# R7FA4W1AD register map
Vendor: Renesas; Series: RA4; File version: 1.0
CPU: CM4 r0p1, little endian, MPU, FPU, VTOR, 4 interrupt priority bits
Registers are 8-bit, read-write, reset 0x0 unless marked. A register's access mark holds for its fields unless they carry their own. Offsets are from the block's base; [hi:lo] are bit positions.

## DMAC0 — Direct memory access controller 0
Base 0x40005000
Same registers: DMAC1 0x40005040, DMAC2 0x40005080, DMAC3 0x400050C0
0x00 DMSAR 32-bit — DMA Source Address Register
  [31:0] DMSAR — Specifies the transfer source start address.
0x04 DMDAR 32-bit — DMA Destination Address Register
  [31:0] DMDAR — Specifies the transfer destination start address.
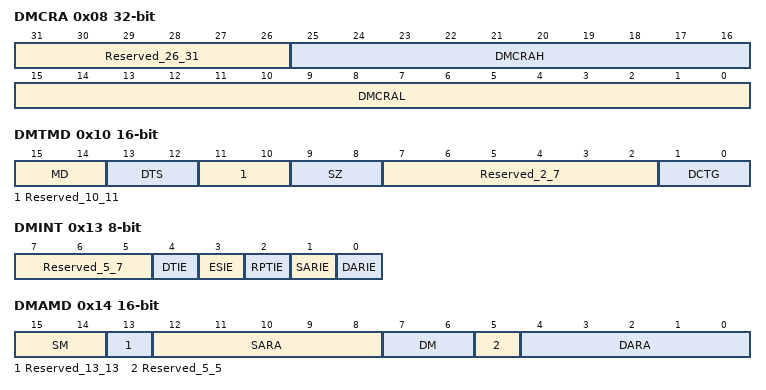
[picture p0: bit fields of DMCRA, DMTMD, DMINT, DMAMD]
0x08 DMCRA 32-bit — DMA Transfer Count Register
  [31:26] Reserved_26_31 — These bits are read as 000000. The write value should be 000000.
  [25:16] DMCRAH — Upper bits of transfer count
  [15:0] DMCRAL — Lower bits of transfer count
0x0C DMCRB 16-bit — DMA Block Transfer Count Register
  [15:0] DMCRB — Specifies the number of block transfer operations or repeat transfer operations.
0x10 DMTMD 16-bit — DMA Transfer Mode Register
  [15:14] MD — Transfer Mode Select
  [13:12] DTS — Repeat Area Select
  [11:10] Reserved_10_11 — These bits are read as 00. The write value should be 00.
  [9:8] SZ — Transfer Data Size Select
  [7:2] Reserved_2_7 — These bits are read as 000000. The write value should be 000000.
  [1:0] DCTG — Transfer Request Source Select
0x13 DMINT — DMA Interrupt Setting Register
  [7:5] Reserved_5_7 — These bits are read as 000. The write value should be 000.
  [4] DTIE — Transfer End Interrupt Enable
  [3] ESIE — Transfer Escape End Interrupt Enable
  [2] RPTIE — Repeat Size End Interrupt Enable
  [1] SARIE — Source Address Extended Repeat Area Overflow Interrupt Enable
  [0] DARIE — Destination Address Extended Repeat Area Overflow Interrupt Enable
0x14 DMAMD 16-bit — DMA Address Mode Register
  [15:14] SM — Source Address Update Mode
  [13] Reserved_13_13 — This bit is read as 0. The write value should be 0.
  [12:8] SARA — Source Address Extended Repeat Area Specifies the extended repeat area on the source address. For details on the settings.
  [7:6] DM — Destination Address Update Mode
  [5] Reserved_5_5 — This bit is read as 0. The write value should be 0.
  [4:0] DARA — Destination Address Extended Repeat Area Specifies the extended repeat area on the destination address. For details on the settings.
0x18 DMOFR 32-bit — DMA Offset Register
  [31:0] DMOFR — Specifies the offset when offset addition is selected as the address update mode for transfer source or destination.
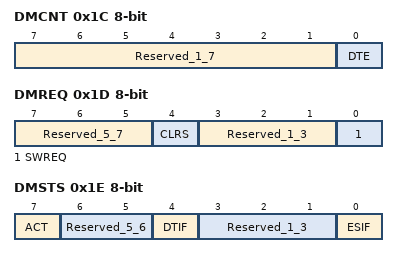
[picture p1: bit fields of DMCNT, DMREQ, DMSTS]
0x1C DMCNT — DMA Transfer Enable Register
  [7:1] Reserved_1_7 — These bits are read as 0000000. The write value should be 0000000.
  [0] DTE read-modifies — DMA Transfer Enable
0x1D DMREQ — DMA Software Start Register
  [7:5] Reserved_5_7 — These bits are read as 000. The write value should be 000.
  [4] CLRS — DMA Software Start Bit Auto Clear Select
  [3:1] Reserved_1_3 — These bits are read as 000. The write value should be 000.
  [0] SWREQ read-modifies — DMA Software Start
0x1E DMSTS — DMA Status Register
  [7] ACT ro — DMA Active Flag
  [6:5] Reserved_5_6 — These bits are read as 00. The write value should be 00.
  [4] DTIF write-0-clears read-modifies — Transfer End Interrupt Flag
  [3:1] Reserved_1_3 — These bits are read as 000. The write value should be 000.
  [0] ESIF write-0-clears read-modifies — Transfer Escape End Interrupt Flag

## DMA — DMAC Module Activation
Base 0x40005200
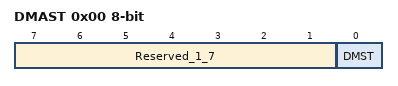
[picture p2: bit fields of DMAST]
0x00 DMAST — DMAC Module Activation Register
  [7:1] Reserved_1_7 — These bits are read as 0000000. The write value should be 0000000.
  [0] DMST — DMAC Operation Enable

## DBG — Debug Function
Base 0x4001B000
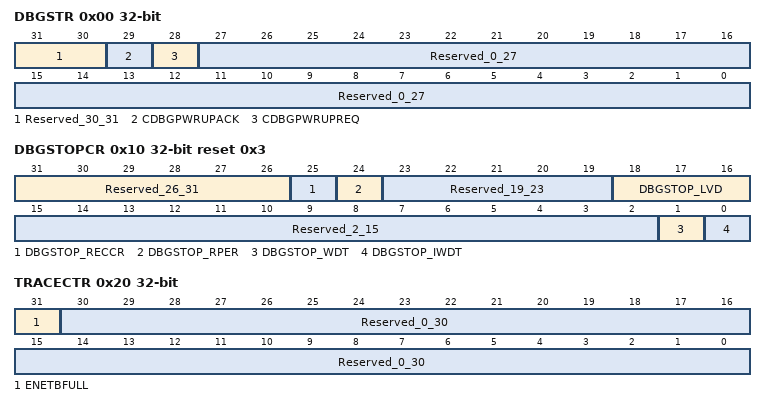
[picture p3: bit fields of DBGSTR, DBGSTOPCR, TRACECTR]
0x00 DBGSTR 32-bit ro — Debug Status Register
  [31:30] Reserved_30_31 — These bits are read as 00.
  [29] CDBGPWRUPACK — Debug power,up acknowledge
  [28] CDBGPWRUPREQ — Debug power,up request
  [27:0] Reserved_0_27 — These bits are read as 0000000000000000000000000000.
0x10 DBGSTOPCR 32-bit reset 0x3 — Debug Stop Control Register
  [31:26] Reserved_26_31 — These bits are read as 000000. The write value should be 000000.
  [25] DBGSTOP_RECCR — Mask bit for RAM ECC error reset/interrupt
  [24] DBGSTOP_RPER — Mask bit for RAM parity error reset/interrupt
  [23:19] Reserved_19_23 — These bits are read as 00000. The write value should be 00000.
  [18:16] DBGSTOP_LVD — b18: Mask bit for LVD2 reset/interrupt (0:enable / 1:Mask)b17: Mask bit for LVD1 reset/interrupt (0:enable / 1:Mask)b16: Mask bit for LVD0 reset (0:enable / 1:Mask)
  [15:2] Reserved_2_15 — These bits are read as 00000000000000. The write value should be 00000000000000.
  [1] DBGSTOP_WDT — Mask bit for WDT reset/interrupt
  [0] DBGSTOP_IWDT — Mask bit for IWDT reset/interrupt
0x20 TRACECTR 32-bit — Trace Control Register
  [31] ENETBFULL — Enable bit for halt request by ETB full
  [30:0] Reserved_0_30 — These bits are read as 0000000000000000000000000000000. The write value should be 0000000000000000000000000000000.
